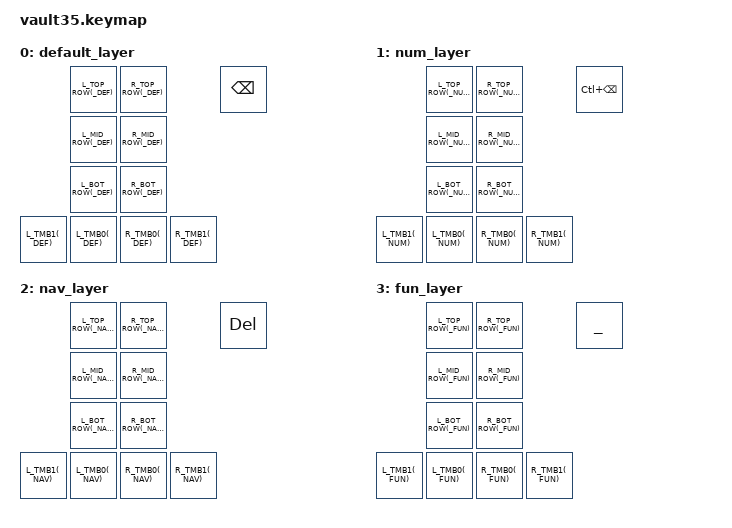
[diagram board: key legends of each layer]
/*
 * Copyright (c) 2020 The ZMK Contributors
 *
 * SPDX-License-Identifier: MIT
 */

#include <behaviors.dtsi>
#include <dt-bindings/zmk/keys.h>

#include "./zmk-nodefree-config/helper.h"
#include "./zmk-nodefree-config/keypos_def/keypos_vault35.h"
#include "./base.keymap"


/* keymap */

ZMK_LAYER(default_layer,
                L_TOP_ROW(_DEF)      R_TOP_ROW(_DEF)             &kp BSPC
                L_MID_ROW(_DEF)      R_MID_ROW(_DEF)
                L_BOT_ROW(_DEF)      R_BOT_ROW(_DEF)
     L_TMB1(_DEF)  L_TMB0(_DEF)      R_TMB0(_DEF)  R_TMB1(_DEF)
)

ZMK_LAYER(num_layer,
                L_TOP_ROW(_NUM)      R_TOP_ROW(_NUM)             &kp LC(BSPC)
                L_MID_ROW(_NUM)      R_MID_ROW(_NUM)
                L_BOT_ROW(_NUM)      R_BOT_ROW(_NUM)
     L_TMB1(_NUM)  L_TMB0(_NUM)      R_TMB0(_NUM)  R_TMB1(_NUM)
)

ZMK_LAYER(nav_layer,
                L_TOP_ROW(_NAV)      R_TOP_ROW(_NAV)    &kp DEL
                L_MID_ROW(_NAV)      R_MID_ROW(_NAV)
                L_BOT_ROW(_NAV)      R_BOT_ROW(_NAV)
     L_TMB1(_NAV)  L_TMB0(_NAV)      R_TMB0(_NAV)  R_TMB1(_NAV)
)

ZMK_LAYER(fun_layer,
                L_TOP_ROW(_FUN)      R_TOP_ROW(_FUN)              ___
                L_MID_ROW(_FUN)      R_MID_ROW(_FUN)
                L_BOT_ROW(_FUN)      R_BOT_ROW(_FUN)
     L_TMB1(_FUN)  L_TMB0(_FUN)      R_TMB0(_FUN)  R_TMB1(_FUN)
)
